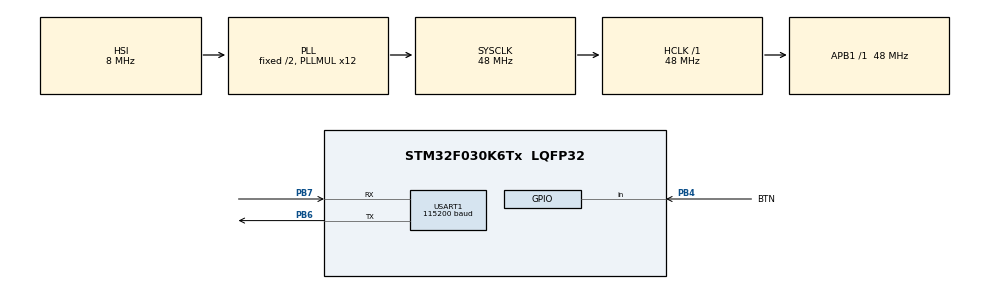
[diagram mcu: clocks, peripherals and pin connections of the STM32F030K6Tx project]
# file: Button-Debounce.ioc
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Mcu.Family=STM32F0
Mcu.Name=STM32F030K6Tx
Mcu.Package=LQFP32
PB4.GPIO_Label=BTN
PB4.Signal=GPIO_Input
PB6.Mode=Asynchronous
PB6.Signal=USART1_TX
PB7.Mode=Asynchronous
PB7.Signal=USART1_RX
ProjectManager.HeapSize=0x200
ProjectManager.StackSize=0x400
ProjectManager.TargetToolchain=MDK-ARM V5
RCC.AHBFreq_Value=48000000
RCC.APB1Freq_Value=48000000
RCC.APB1TimFreq_Value=48000000
RCC.FLatency=FLASH_LATENCY_1
RCC.HCLKFreq_Value=48000000
RCC.PLLMUL=RCC_PLL_MUL12
RCC.SYSCLKFreq_VALUE=48000000
RCC.SYSCLKSource=RCC_SYSCLKSOURCE_PLLCLK
USART1.BaudRate=115200
USART1.VirtualMode-Asynchronous=VM_ASYNC
board=custom

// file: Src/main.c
/* USER CODE BEGIN Header */
/**
  ******************************************************************************
  * @file           : main.c
  * @brief          : Main program body
  ******************************************************************************
  ** This notice applies to any and all portions of this file
  * that are not between comment pairs USER CODE BEGIN and
  * USER CODE END. Other portions of this file, whether
  * inserted by the user or by software development tools
  * are owned by their respective copyright owners.
  *
  * COPYRIGHT(c) 2019 STMicroelectronics
  *
  * Redistribution and use in source and binary forms, with or without modification,
  * are permitted provided that the following conditions are met:
  *   1. Redistributions of source code must retain the above copyright notice,
  *      this list of conditions and the following disclaimer.
  *   2. Redistributions in binary form must reproduce the above copyright notice,
  *      this list of conditions and the following disclaimer in the documentation
  *      and/or other materials provided with the distribution.
  *   3. Neither the name of STMicroelectronics nor the names of its contributors
  *      may be used to endorse or promote products derived from this software
  *      without specific prior written permission.
  *
  * THIS SOFTWARE IS PROVIDED BY THE COPYRIGHT HOLDERS AND CONTRIBUTORS "AS IS"
  * AND ANY EXPRESS OR IMPLIED WARRANTIES, INCLUDING, BUT NOT LIMITED TO, THE
  * IMPLIED WARRANTIES OF MERCHANTABILITY AND FITNESS FOR A PARTICULAR PURPOSE ARE
  * DISCLAIMED. IN NO EVENT SHALL THE COPYRIGHT HOLDER OR CONTRIBUTORS BE LIABLE
  * FOR ANY DIRECT, INDIRECT, INCIDENTAL, SPECIAL, EXEMPLARY, OR CONSEQUENTIAL
  * DAMAGES (INCLUDING, BUT NOT LIMITED TO, PROCUREMENT OF SUBSTITUTE GOODS OR
  * SERVICES; LOSS OF USE, DATA, OR PROFITS; OR BUSINESS INTERRUPTION) HOWEVER
  * CAUSED AND ON ANY THEORY OF LIABILITY, WHETHER IN CONTRACT, STRICT LIABILITY,
  * OR TORT (INCLUDING NEGLIGENCE OR OTHERWISE) ARISING IN ANY WAY OUT OF THE USE
  * OF THIS SOFTWARE, EVEN IF ADVISED OF THE POSSIBILITY OF SUCH DAMAGE.
  *
  ******************************************************************************
  */
/* USER CODE END Header */

#include "main.h"

/* USER CODE BEGIN Includes */
#include "stdio-port-stm32.h"
#include "utility.h"
#include "button.h"
/* USER CODE END Includes */

UART_HandleTypeDef huart1;

/* USER CODE BEGIN PV */
button_t btn;
bool longpress = false;
bool longrelease = false;
bool state;
bool filter;
int counter = 0;

uint32_t print_time;
/* USER CODE END PV */

void SystemClock_Config(void);
static void MX_GPIO_Init(void);
static void MX_USART1_UART_Init(void);

int main(void)
{

  /* MCU Configuration--------------------------------------------------------*/

  /* Reset of all peripherals, Initializes the Flash interface and the Systick. */
  HAL_Init();

  /* Configure the system clock */
  SystemClock_Config();

  /* Initialize all configured peripherals */
  MX_GPIO_Init();
  MX_USART1_UART_Init();
  /* USER CODE BEGIN 2 */
  button_create(&btn, (uint32_t *)&GPIOB->IDR, GPIO_PIN_4, active_low);
  /* USER CODE END 2 */

  /* Infinite loop */
  /* USER CODE BEGIN WHILE */
  uint32_t longpress_inc_time = 0;
  while (1)
  {

    button_read(&btn);

    if (button_wasPressed(&btn))
    {
      counter += 1;
    }

    if (button_pressedFor(&btn, 1000))
    {
      if (HAL_GetTick() - longpress_inc_time > 500)
      {
        longpress_inc_time = HAL_GetTick();
        counter += 5;
      }
    }

    if (HAL_GetTick() - print_time > 500)
    {
      print_time = HAL_GetTick();
      printf("$%d;", counter);
    }

    /* USER CODE END WHILE */

  }
}

void SystemClock_Config(void)
{
  RCC_OscInitTypeDef RCC_OscInitStruct = {0};
  RCC_ClkInitTypeDef RCC_ClkInitStruct = {0};
  RCC_PeriphCLKInitTypeDef PeriphClkInit = {0};

  /**Initializes the CPU, AHB and APB busses clocks
  */
  RCC_OscInitStruct.OscillatorType = RCC_OSCILLATORTYPE_HSI;
  RCC_OscInitStruct.HSIState = RCC_HSI_ON;
  RCC_OscInitStruct.HSICalibrationValue = RCC_HSICALIBRATION_DEFAULT;
  RCC_OscInitStruct.PLL.PLLState = RCC_PLL_ON;
  RCC_OscInitStruct.PLL.PLLSource = RCC_PLLSOURCE_HSI;
  RCC_OscInitStruct.PLL.PLLMUL = RCC_PLL_MUL12;
  RCC_OscInitStruct.PLL.PREDIV = RCC_PREDIV_DIV1;
  if (HAL_RCC_OscConfig(&RCC_OscInitStruct) != HAL_OK)
  {
    Error_Handler();
  }
  /**Initializes the CPU, AHB and APB busses clocks
  */
  RCC_ClkInitStruct.ClockType = RCC_CLOCKTYPE_HCLK|RCC_CLOCKTYPE_SYSCLK
                              |RCC_CLOCKTYPE_PCLK1;
  RCC_ClkInitStruct.SYSCLKSource = RCC_SYSCLKSOURCE_PLLCLK;
  RCC_ClkInitStruct.AHBCLKDivider = RCC_SYSCLK_DIV1;
  RCC_ClkInitStruct.APB1CLKDivider = RCC_HCLK_DIV1;

  if (HAL_RCC_ClockConfig(&RCC_ClkInitStruct, FLASH_LATENCY_1) != HAL_OK)
  {
    Error_Handler();
  }
  PeriphClkInit.PeriphClockSelection = RCC_PERIPHCLK_USART1;
  PeriphClkInit.Usart1ClockSelection = RCC_USART1CLKSOURCE_PCLK1;
  if (HAL_RCCEx_PeriphCLKConfig(&PeriphClkInit) != HAL_OK)
  {
    Error_Handler();
  }
}

static void MX_USART1_UART_Init(void)
{

  huart1.Instance = USART1;
  huart1.Init.BaudRate = 115200;
  huart1.Init.WordLength = UART_WORDLENGTH_8B;
  huart1.Init.StopBits = UART_STOPBITS_1;
  huart1.Init.Parity = UART_PARITY_NONE;
  huart1.Init.Mode = UART_MODE_TX_RX;
  huart1.Init.HwFlowCtl = UART_HWCONTROL_NONE;
  huart1.Init.OverSampling = UART_OVERSAMPLING_16;
  huart1.Init.OneBitSampling = UART_ONE_BIT_SAMPLE_DISABLE;
  huart1.AdvancedInit.AdvFeatureInit = UART_ADVFEATURE_NO_INIT;
  if (HAL_UART_Init(&huart1) != HAL_OK)
  {
    Error_Handler();
  }

}

static void MX_GPIO_Init(void)
{
  GPIO_InitTypeDef GPIO_InitStruct = {0};

  /* GPIO Ports Clock Enable */
  __HAL_RCC_GPIOB_CLK_ENABLE();

  /*Configure GPIO pin : BTN_Pin */
  GPIO_InitStruct.Pin = BTN_Pin;
  GPIO_InitStruct.Mode = GPIO_MODE_INPUT;
  GPIO_InitStruct.Pull = GPIO_NOPULL;
  HAL_GPIO_Init(BTN_GPIO_Port, &GPIO_InitStruct);

}

void Error_Handler(void)
{
}

/************************ (C) COPYRIGHT STMicroelectronics *****END OF FILE****/
